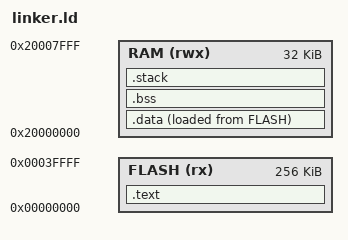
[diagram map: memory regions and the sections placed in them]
MEMORY
{
    FLASH (rx) : ORIGIN = 0x00000000, LENGTH = 256K
    RAM (rwx) : ORIGIN = 0x20000000, LENGTH = 32K
}

SECTIONS
{
    .text :
    {
        KEEP(*(.vectors))
        *(.text*)
        *(.rodata*)
        . = ALIGN(4);
        _etext = .;
    } > FLASH

    .data :
    {
        _sdata = .;
        *(.data*)
        . = ALIGN(4);
        _edata = .;
    } > RAM AT> FLASH
    _sidata = LOADADDR(.data);

    .bss :
    {
        _sbss = .;
        *(.bss*)
        *(COMMON)
        . = ALIGN(4);
        _ebss = .;
    } > RAM

    .stack :
    {
        . = ALIGN(8);
        . = . + 0x1000;
        _estack = .;
    } > RAM
}
